# nRF54h20_radiocore register map
Vendor: Nordic Semiconductor; Series: nRF54h; File version: 1
CPU: CM33 r0p4, little endian, MPU, FPU, 3 interrupt priority bits, 480 interrupts, 8 SAU regions
Registers are 32-bit, read-write, reset 0x0 unless marked. A register's access mark holds for its fields unless they carry their own. Offsets are from the block's base; [hi:lo] are bit positions; {n}, {i} and the like mark numbered series; 'fields as' and 'values as' point back to an identical list.

## GLOBAL_SECDOMBELLBOARD_NS — BELLBOARD public registers 0
Base 0x4F099000
Same registers: GLOBAL_SECDOMBELLBOARD_S 0x5F099000
{0x0+4i} TASKS_TRIGGER[{i}] (i=0..31) wo — Description collection: Task TRIGGER[n]
  [0] TASKS_TRIGGER — Task TRIGGER[n]
    1=Trigger task

## GLOBAL_VPR120_NS — VPR peripheral registers 0
Base 0x4F8C8000
Same registers: GLOBAL_VPR120_S 0x5F8C8000
{0x0+4i} TASKS_TRIGGER[{i}] (i=0..31) wo — Description collection: VPR task [n] register
  [0] TASKS_TRIGGER — VPR task [n] register
    1=Trigger task

## GLOBAL_MUTEX120_NS — MUTEX 0
Base 0x4F8D2000
Same registers: GLOBAL_MUTEX130_NS 0x4F927000
{0x400+4i} MUTEX[{i}] (i=0..31) — Description collection: Mutex register
  [0] MUTEX — Mutex register n
    0=Unlocked (Mutex n is in unlocked state); 1=Locked (Mutex n is in locked state)

## GLOBAL_CAN120_NS — Controller Area Network 0
Base 0x4F8D8000
Same registers: GLOBAL_CAN120_S 0x5F8D8000
0x00 TASKS_START wo — Start the CAN peripheral.
  [0] TASKS_START
    1=Trigger task
0x04 TASKS_STOPREQ wo — Request to stop the CAN peripheral
  [0] TASKS_STOPREQ
    1=Trigger task
0x08 TASKS_STOP wo — Stop the CAN peripheral
  [0] TASKS_STOP
    1=Trigger task
{0x100+4i} EVENTS_CORE[{i}] (i=0..1) — Description collection: Event indicating that interrupt n triggered at CAN core
  [0] EVENTS_CORE — Event indicating that interrupt n triggered at CAN core
    0=NotGenerated (Event not generated); 1=Generated (Event generated)
0x108 EVENTS_DMU — Event indicating that interrupt triggered at CAN DMU
  [0] EVENTS_DMU
    values as EVENTS_CORE[0].EVENTS_CORE
0x10C EVENTS_DMA — Event indicating that interrupt triggered at CAN DMA
  [0] EVENTS_DMA
    values as EVENTS_CORE[0].EVENTS_CORE
0x110 EVENTS_READYFORSTOP — Event indicating that the CAN is ready to be stopped
  [0] EVENTS_READYFORSTOP
    values as EVENTS_CORE[0].EVENTS_CORE
0x200 SHORTS — Shortcuts between local events and tasks
  [0] READYFORSTOP_STOP — Shortcut between event READYFORSTOP and task STOP
    0=Disabled (Disable shortcut); 1=Enabled (Enable shortcut)
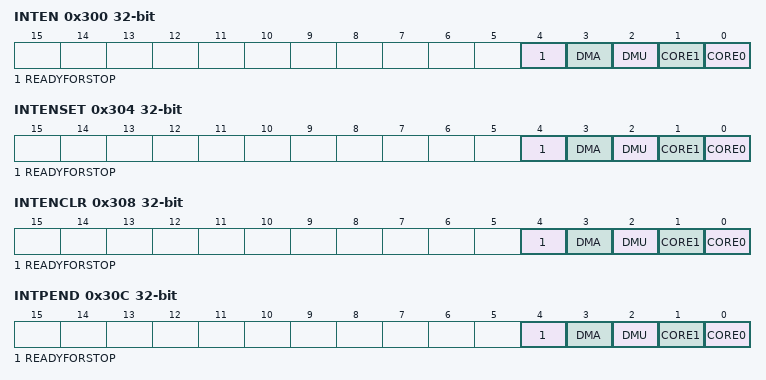
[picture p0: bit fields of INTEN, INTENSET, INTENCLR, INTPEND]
0x300 INTEN — Enable or disable interrupt
  [all] fields
    0=Disabled; 1=Enabled
  [4] READYFORSTOP — Enable or disable interrupt for event READYFORSTOP
  [3] DMA — Enable or disable interrupt for event DMA
  [2] DMU — Enable or disable interrupt for event DMU
  [1] CORE1 — Enable or disable interrupt for event CORE[1]
  [0] CORE0 — Enable or disable interrupt for event CORE[0]
0x304 INTENSET — Enable interrupt
  [all] fields
    on read: 0=Disabled (Read: Disabled); 1=Enabled (Read: Enabled) | on write: 1=Set (Enable)
  [4] READYFORSTOP — Write '1' to enable interrupt for event READYFORSTOP
  [3] DMA — Write '1' to enable interrupt for event DMA
  [2] DMU — Write '1' to enable interrupt for event DMU
  [1] CORE1 — Write '1' to enable interrupt for event CORE[1]
  [0] CORE0 — Write '1' to enable interrupt for event CORE[0]
0x308 INTENCLR — Disable interrupt
  [all] fields
    on read: 0=Disabled (Read: Disabled); 1=Enabled (Read: Enabled) | on write: 1=Clear (Disable)
  [4] READYFORSTOP — Write '1' to disable interrupt for event READYFORSTOP
  [3] DMA — Write '1' to disable interrupt for event DMA
  [2] DMU — Write '1' to disable interrupt for event DMU
  [1] CORE1 — Write '1' to disable interrupt for event CORE[1]
  [0] CORE0 — Write '1' to disable interrupt for event CORE[0]
0x30C INTPEND ro — Pending interrupts
  [all] fields
    on read: 0=NotPending (Read: Not pending); 1=Pending (Read: Pending)
  [4] READYFORSTOP — Read pending status of interrupt for event READYFORSTOP
  [3] DMA — Read pending status of interrupt for event DMA
  [2] DMU — Read pending status of interrupt for event DMU
  [1] CORE1 — Read pending status of interrupt for event CORE[1]
  [0] CORE0 — Read pending status of interrupt for event CORE[0]

## GLOBAL_RAMC122_NS — RAM Controller 0
Base 0x4F8DA000
Same registers: GLOBAL_RAMC122_S 0x5F8DA000
0x500 WAITSTATES — Waitstates for read operations.
  [0] WAITSTATES — Number of waitstates for a read from the RAM.

## GLOBAL_TEMP_NS — Temperature Sensor 0
Base 0x4F984000
Same registers: GLOBAL_TEMP_S 0x5F984000
0x00 TASKS_START wo — Start temperature measurement
  [0] TASKS_START
    1=Trigger task
0x04 TASKS_STOP wo — Stop temperature measurement
  [0] TASKS_STOP
    1=Trigger task
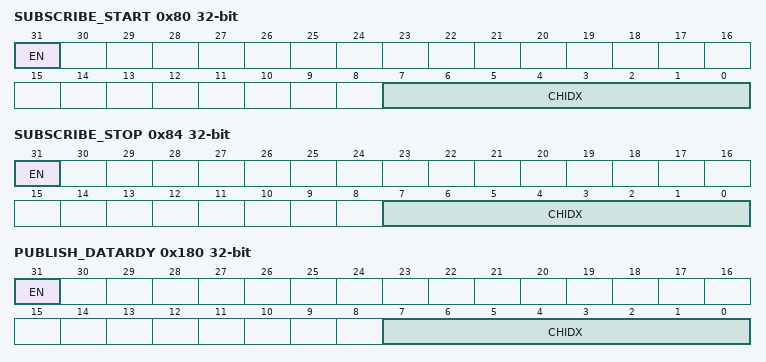
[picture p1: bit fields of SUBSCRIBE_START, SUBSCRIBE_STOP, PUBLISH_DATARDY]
0x80 SUBSCRIBE_START — Subscribe configuration for task START
  [31] EN
    0=Disabled (Disable subscription); 1=Enabled (Enable subscription)
  [7:0] CHIDX — DPPI channel that task START will subscribe to
0x84 SUBSCRIBE_STOP — Subscribe configuration for task STOP
  [31] EN
    values as SUBSCRIBE_START.EN
  [7:0] CHIDX — DPPI channel that task STOP will subscribe to
0x100 EVENTS_DATARDY — Temperature measurement complete, data ready
  [0] EVENTS_DATARDY
    0=NotGenerated (Event not generated); 1=Generated (Event generated)
0x180 PUBLISH_DATARDY — Publish configuration for event DATARDY
  [31] EN
    0=Disabled (Disable publishing); 1=Enabled (Enable publishing)
  [7:0] CHIDX — DPPI channel that event DATARDY will publish to
0x304 INTENSET — Enable interrupt
  [0] DATARDY — Write '1' to enable interrupt for event DATARDY
    on read: 0=Disabled (Read: Disabled); 1=Enabled (Read: Enabled) | on write: 1=Set (Enable)
0x308 INTENCLR — Disable interrupt
  [0] DATARDY — Write '1' to disable interrupt for event DATARDY
    on read: 0=Disabled (Read: Disabled); 1=Enabled (Read: Enabled) | on write: 1=Clear (Disable)
0x508 TEMP ro — Temperature in degC (0.25deg steps)
0x520 A0 reset 0x276 — Slope of 1st piece wise linear function
  [11:0] A0
0x524 A1 reset 0x324 — Slope of 2nd piece wise linear function
  [11:0] A1
0x528 A2 reset 0x3AB — Slope of 3rd piece wise linear function
  [11:0] A2
0x52C A3 reset 0x453 — Slope of 4th piece wise linear function
  [11:0] A3
0x530 A4 reset 0x49B — Slope of 5th piece wise linear function
  [11:0] A4
0x534 A5 reset 0x550 — Slope of 6th piece wise linear function
  [11:0] A5
0x538 A6 reset 0x67E — Slope of 7th piece wise linear function
  [11:0] A6
0x540 B0 reset 0xFA6 — y-intercept of 1st piece wise linear function
  [11:0] B0
0x544 B1 reset 0xF35 — y-intercept of 2nd piece wise linear function
  [11:0] B1
0x548 B2 reset 0xFAA — y-intercept of 3rd piece wise linear function
  [11:0] B2
0x54C B3 reset 0x7E — y-intercept of 4th piece wise linear function
  [11:0] B3
0x550 B4 reset 0xEA — y-intercept of 5th piece wise linear function
  [11:0] B4
0x554 B5 reset 0x1ED — y-intercept of 6th piece wise linear function
  [11:0] B5
0x558 B6 reset 0x378 — y-intercept of 7th piece wise linear function
  [11:0] B6
0x560 T0 reset 0xED — End point of 1st piece wise linear function
  [7:0] T0
0x564 T1 reset 0x13 — End point of 2nd piece wise linear function
  [7:0] T1
0x568 T2 reset 0x29 — End point of 3rd piece wise linear function
  [7:0] T2
0x56C T3 reset 0x3C — End point of 4th piece wise linear function
  [7:0] T3
0x570 T4 reset 0x44 — End point of 5th piece wise linear function
  [7:0] T4
0x574 T5 reset 0x53 — End point of 6th piece wise linear function
  [7:0] T5

## Notices in the file
Copyright (c) 2010 - 2025, Nordic Semiconductor ASA All rights reserved.
SPDX-License-Identifier: BSD-3-Clause
Redistribution and use in source and binary forms, with or without
modification, are permitted provided that the following conditions are met:
1. Redistributions of source code must retain the above copyright notice, this
list of conditions and the following disclaimer.
2. Redistributions in binary form must reproduce the above copyright
notice, this list of conditions and the following disclaimer in the
documentation and/or other materials provided with the distribution.
3. Neither the name of Nordic Semiconductor ASA nor the names of its
contributors may be used to endorse or promote products derived from this
software without specific prior written permission.
THIS SOFTWARE IS PROVIDED BY THE COPYRIGHT HOLDERS AND CONTRIBUTORS "AS IS"
AND ANY EXPRESS OR IMPLIED WARRANTIES, INCLUDING, BUT NOT LIMITED TO, THE
IMPLIED WARRANTIES OF MERCHANTABILITY, AND FITNESS FOR A PARTICULAR PURPOSE
ARE DISCLAIMED. IN NO EVENT SHALL NORDIC SEMICONDUCTOR ASA OR CONTRIBUTORS BE
LIABLE FOR ANY DIRECT, INDIRECT, INCIDENTAL, SPECIAL, EXEMPLARY, OR
CONSEQUENTIAL DAMAGES (INCLUDING, BUT NOT LIMITED TO, PROCUREMENT OF
SUBSTITUTE GOODS OR SERVICES; LOSS OF USE, DATA, OR PROFITS; OR BUSINESS
INTERRUPTION) HOWEVER CAUSED AND ON ANY THEORY OF LIABILITY, WHETHER IN
CONTRACT, STRICT LIABILITY, OR TORT (INCLUDING NEGLIGENCE OR OTHERWISE)
ARISING IN ANY WAY OUT OF THE USE OF THIS SOFTWARE, EVEN IF ADVISED OF THE
POSSIBILITY OF SUCH DAMAGE.
